# ioat91sam7x256 register map
Registers are 32-bit, access not given, no defined reset value unless marked. A register's access mark holds for its fields unless they carry their own. Addresses are absolute; registers are grouped by the start of their names; [hi:lo] are bit positions; {n}, {i} and the like mark numbered series; 'fields as' and 'values as' point back to an identical list.

## US0
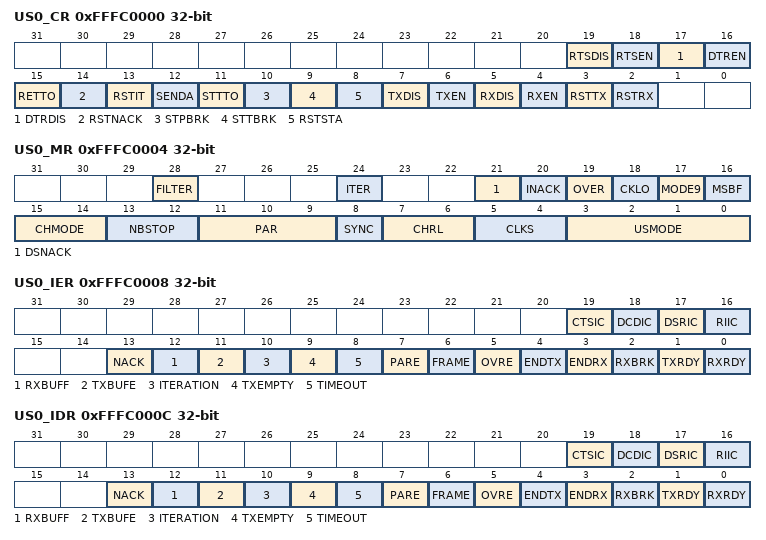
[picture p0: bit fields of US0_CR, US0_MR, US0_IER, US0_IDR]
0xFFFC0000 US0_CR
  [19] RTSDIS, [18] RTSEN, [17] DTRDIS, [16] DTREN, [15] RETTO, [14] RSTNACK, [13] RSTIT, [12] SENDA, [11] STTTO, [10] STPBRK, [9] STTBRK, [8] RSTSTA, [7] TXDIS, [6] TXEN, [5] RXDIS, [4] RXEN, [3] RSTTX, [2] RSTRX
0xFFFC0004 US0_MR
  [28] FILTER, [24] ITER, [21] DSNACK, [20] INACK, [19] OVER, [18] CKLO, [17] MODE9, [16] MSBF, [15:14] CHMODE, [13:12] NBSTOP, [11:9] PAR, [8] SYNC, [7:6] CHRL, [5:4] CLKS, [3:0] USMODE
0xFFFC0008 US0_IER
  [19] CTSIC, [18] DCDIC, [17] DSRIC, [16] RIIC, [13] NACK, [12] RXBUFF, [11] TXBUFE, [10] ITERATION, [9] TXEMPTY, [8] TIMEOUT, [7] PARE, [6] FRAME, [5] OVRE, [4] ENDTX, [3] ENDRX, [2] RXBRK, [1] TXRDY, [0] RXRDY
0xFFFC000C US0_IDR
  fields as US0_IER
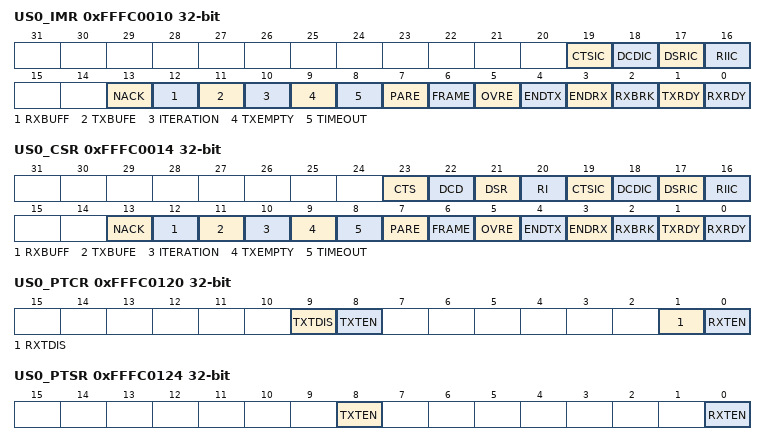
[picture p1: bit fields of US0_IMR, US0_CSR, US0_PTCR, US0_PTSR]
0xFFFC0010 US0_IMR
  fields as US0_IER
0xFFFC0014 US0_CSR
  [23] CTS, [22] DCD, [21] DSR, [20] RI, [19] CTSIC, [18] DCDIC, [17] DSRIC, [16] RIIC, [13] NACK, [12] RXBUFF, [11] TXBUFE, [10] ITERATION, [9] TXEMPTY, [8] TIMEOUT, [7] PARE, [6] FRAME, [5] OVRE, [4] ENDTX, [3] ENDRX, [2] RXBRK, [1] TXRDY, [0] RXRDY
0xFFFC0018 US0_RHR
0xFFFC001C US0_THR
0xFFFC0020 US0_BRGR
0xFFFC0024 US0_RTOR
0xFFFC0028 US0_TTGR
0xFFFC0040 US0_FIDI
0xFFFC0044 US0_NER
0xFFFC004C US0_IF
0xFFFC0100 US0_RPR
0xFFFC0104 US0_RCR
0xFFFC0108 US0_TPR
0xFFFC010C US0_TCR
0xFFFC0110 US0_RNPR
0xFFFC0114 US0_RNCR
0xFFFC0118 US0_TNPR
0xFFFC011C US0_TNCR
0xFFFC0120 US0_PTCR
  [9] TXTDIS, [8] TXTEN, [1] RXTDIS, [0] RXTEN
0xFFFC0124 US0_PTSR
  [8] TXTEN, [0] RXTEN

## SSC
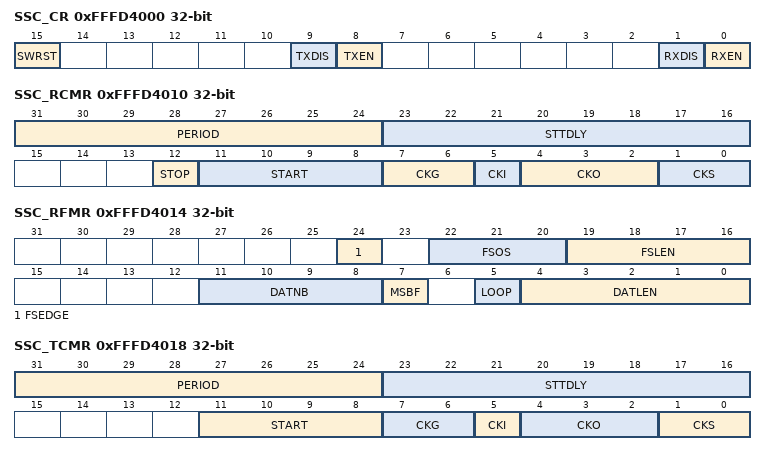
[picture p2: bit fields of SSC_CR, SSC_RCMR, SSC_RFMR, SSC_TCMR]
0xFFFD4000 SSC_CR
  [15] SWRST, [9] TXDIS, [8] TXEN, [1] RXDIS, [0] RXEN
0xFFFD4004 SSC_CMR
0xFFFD4010 SSC_RCMR
  [31:24] PERIOD, [23:16] STTDLY, [12] STOP, [11:8] START, [7:6] CKG, [5] CKI, [4:2] CKO, [1:0] CKS
0xFFFD4014 SSC_RFMR
  [24] FSEDGE, [22:20] FSOS, [19:16] FSLEN, [11:8] DATNB, [7] MSBF, [5] LOOP, [4:0] DATLEN
0xFFFD4018 SSC_TCMR
  [31:24] PERIOD, [23:16] STTDLY, [11:8] START, [7:6] CKG, [5] CKI, [4:2] CKO, [1:0] CKS
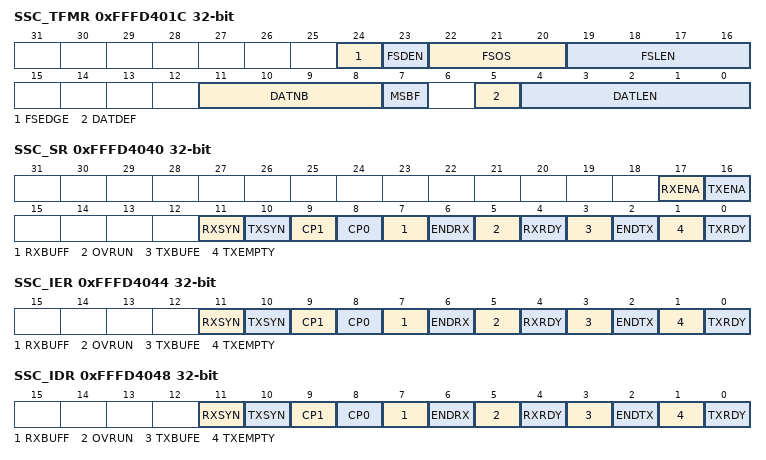
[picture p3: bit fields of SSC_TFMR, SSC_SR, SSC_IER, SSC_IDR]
0xFFFD401C SSC_TFMR
  [24] FSEDGE, [23] FSDEN, [22:20] FSOS, [19:16] FSLEN, [11:8] DATNB, [7] MSBF, [5] DATDEF, [4:0] DATLEN
0xFFFD4020 SSC_RHR
0xFFFD4024 SSC_THR
0xFFFD4030 SSC_RSHR
0xFFFD4034 SSC_TSHR
0xFFFD4040 SSC_SR
  [17] RXENA, [16] TXENA, [11] RXSYN, [10] TXSYN, [9] CP1, [8] CP0, [7] RXBUFF, [6] ENDRX, [5] OVRUN, [4] RXRDY, [3] TXBUFE, [2] ENDTX, [1] TXEMPTY, [0] TXRDY
0xFFFD4044 SSC_IER
  [11] RXSYN, [10] TXSYN, [9] CP1, [8] CP0, [7] RXBUFF, [6] ENDRX, [5] OVRUN, [4] RXRDY, [3] TXBUFE, [2] ENDTX, [1] TXEMPTY, [0] TXRDY
0xFFFD4048 SSC_IDR
  fields as SSC_IER
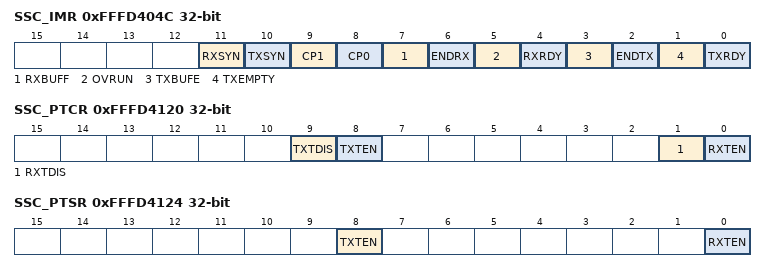
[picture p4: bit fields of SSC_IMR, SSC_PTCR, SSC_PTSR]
0xFFFD404C SSC_IMR
  fields as SSC_IER
0xFFFD4100 SSC_RPR
0xFFFD4104 SSC_RCR
0xFFFD4108 SSC_TPR
0xFFFD410C SSC_TCR
0xFFFD4110 SSC_RNPR
0xFFFD4114 SSC_RNCR
0xFFFD4118 SSC_TNPR
0xFFFD411C SSC_TNCR
0xFFFD4120 SSC_PTCR
  [9] TXTDIS, [8] TXTEN, [1] RXTDIS, [0] RXTEN
0xFFFD4124 SSC_PTSR
  [8] TXTEN, [0] RXTEN

## TWI
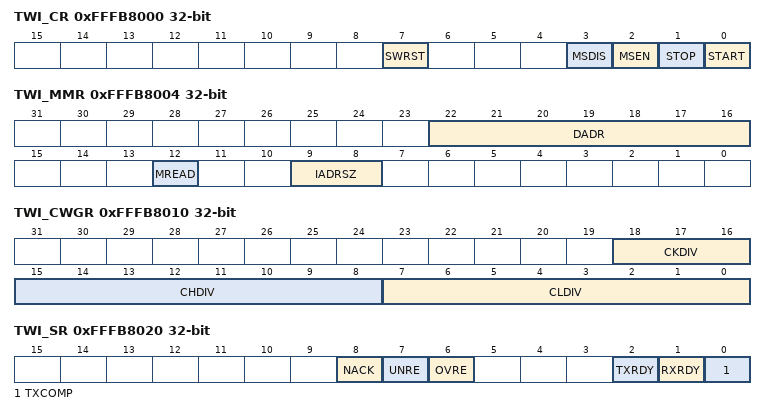
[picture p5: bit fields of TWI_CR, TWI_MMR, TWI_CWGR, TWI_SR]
0xFFFB8000 TWI_CR
  [7] SWRST, [3] MSDIS, [2] MSEN, [1] STOP, [0] START
0xFFFB8004 TWI_MMR
  [22:16] DADR, [12] MREAD, [9:8] IADRSZ
0xFFFB800C TWI_IADR
0xFFFB8010 TWI_CWGR
  [18:16] CKDIV, [15:8] CHDIV, [7:0] CLDIV
0xFFFB8020 TWI_SR
  [8] NACK, [7] UNRE, [6] OVRE, [2] TXRDY, [1] RXRDY, [0] TXCOMP
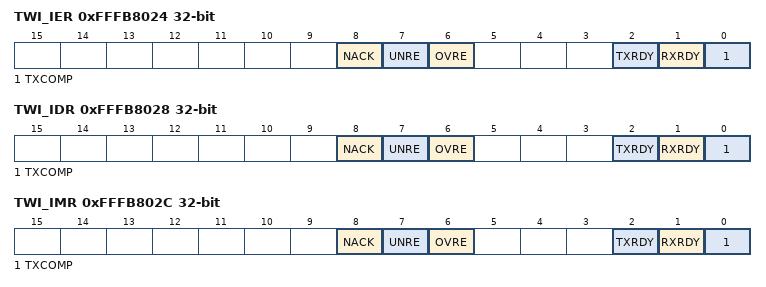
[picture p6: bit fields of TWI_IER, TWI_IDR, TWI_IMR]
0xFFFB8024 TWI_IER
  [8] NACK, [7] UNRE, [6] OVRE, [2] TXRDY, [1] RXRDY, [0] TXCOMP
0xFFFB8028 TWI_IDR
  [8] NACK, [7] UNRE, [6] OVRE, [2] TXRDY, [1] RXRDY, [0] TXCOMP
0xFFFB802C TWI_IMR
  [8] NACK, [7] UNRE, [6] OVRE, [2] TXRDY, [1] RXRDY, [0] TXCOMP
0xFFFB8030 TWI_RHR
0xFFFB8034 TWI_THR

## PWMC
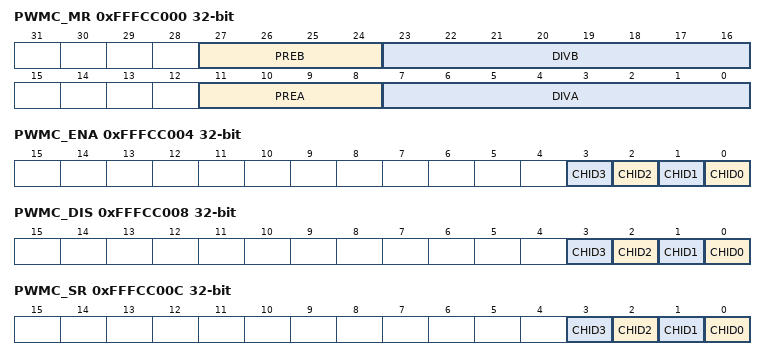
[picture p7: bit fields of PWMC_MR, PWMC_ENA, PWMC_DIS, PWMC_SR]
0xFFFCC000 PWMC_MR
  [27:24] PREB, [23:16] DIVB, [11:8] PREA, [7:0] DIVA
0xFFFCC004 PWMC_ENA
  [n] CHID{n} (n=0..3)
0xFFFCC008 PWMC_DIS
  [n] CHID{n} (n=0..3)
0xFFFCC00C PWMC_SR
  [n] CHID{n} (n=0..3)
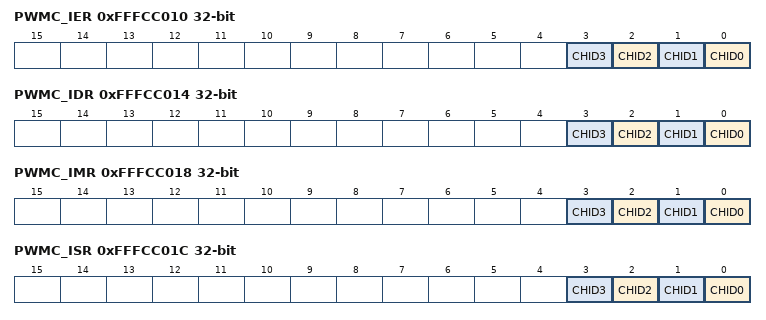
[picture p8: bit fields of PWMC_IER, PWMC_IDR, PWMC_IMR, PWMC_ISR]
0xFFFCC010 PWMC_IER
  [n] CHID{n} (n=0..3)
0xFFFCC014 PWMC_IDR
  [n] CHID{n} (n=0..3)
0xFFFCC018 PWMC_IMR
  [n] CHID{n} (n=0..3)
0xFFFCC01C PWMC_ISR
  [n] CHID{n} (n=0..3)
0xFFFCC0FC PWMC_VR
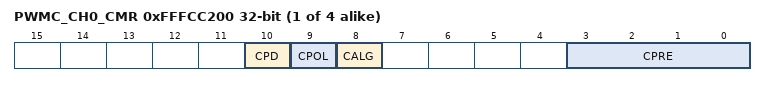
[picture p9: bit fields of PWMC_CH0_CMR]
{0xFFFCC200+0x20*i} PWMC_CH{i}_CMR (i=0..3)
  [10] CPD, [9] CPOL, [8] CALG, [3:0] CPRE
{0xFFFCC204+0x20*i} PWMC_CH{i}_CDTYR (i=0..3)
  [31:0] CDTY
{0xFFFCC208+0x20*i} PWMC_CH{i}_CPRDR (i=0..3)
  [31:0] CPRD
{0xFFFCC20C+0x20*i} PWMC_CH{i}_CCNTR (i=0..3)
  [31:0] CCNT
{0xFFFCC210+0x20*i} PWMC_CH{i}_CUPDR (i=0..3)
  [31:0] CUPD
{0xFFFCC214+0x20*i} PWMC_CH{i}_Reserved (i=0..3)
